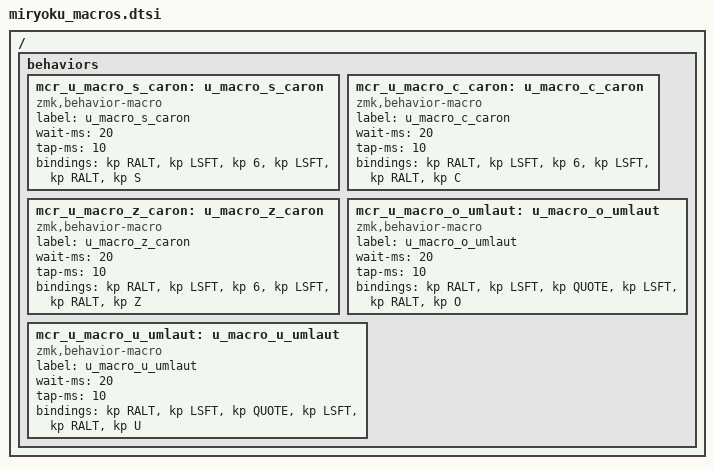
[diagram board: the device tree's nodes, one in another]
/ {
	behaviors {
		mcr_u_macro_s_caron: u_macro_s_caron {
			label = "u_macro_s_caron";
			compatible = "zmk,behavior-macro";
			#binding-cells = <0>;
			wait-ms = <20>;
			tap-ms = <10>;
			bindings = <&kp RALT>, <&kp LSFT>, <&kp 6>, <&kp LSFT>, <&kp RALT>, <&kp S>;
		};

		mcr_u_macro_c_caron: u_macro_c_caron {
			label = "u_macro_c_caron";
			compatible = "zmk,behavior-macro";
			#binding-cells = <0>;
			wait-ms = <20>;
			tap-ms = <10>;
			bindings = <&kp RALT>, <&kp LSFT>, <&kp 6>, <&kp LSFT>, <&kp RALT>, <&kp C>;
		};

		mcr_u_macro_z_caron: u_macro_z_caron {
			label = "u_macro_z_caron";
			compatible = "zmk,behavior-macro";
			#binding-cells = <0>;
			wait-ms = <20>;
			tap-ms = <10>;
			bindings = <&kp RALT>, <&kp LSFT>, <&kp 6>, <&kp LSFT>, <&kp RALT>, <&kp Z>;
		};

		mcr_u_macro_o_umlaut: u_macro_o_umlaut {
			label = "u_macro_o_umlaut";
			compatible = "zmk,behavior-macro";
			#binding-cells = <0>;
			wait-ms = <20>;
			tap-ms = <10>;
			bindings = <&kp RALT>, <&kp LSFT>, <&kp QUOTE>, <&kp LSFT>, <&kp RALT>, <&kp O>;
		};

		mcr_u_macro_u_umlaut: u_macro_u_umlaut {
			label = "u_macro_u_umlaut";
			compatible = "zmk,behavior-macro";
			#binding-cells = <0>;
			wait-ms = <20>;
			tap-ms = <10>;
			bindings = <&kp RALT>, <&kp LSFT>, <&kp QUOTE>, <&kp LSFT>, <&kp RALT>, <&kp U>;
		};
	};
};
